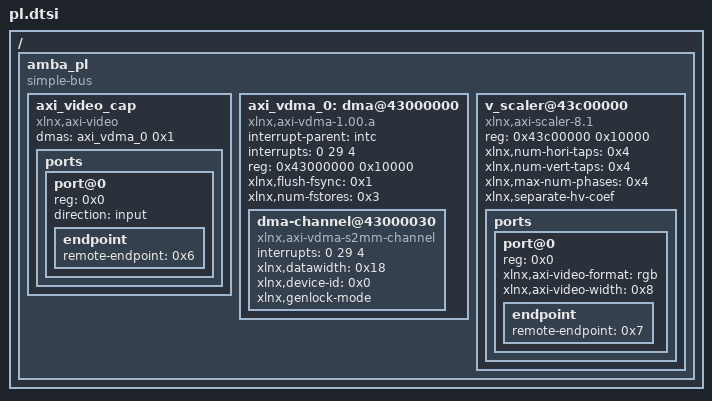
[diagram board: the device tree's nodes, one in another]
/*
 * CAUTION: This file is automatically generated by Xilinx.
 * Version:  
 * Today is: Sat Mar 12 11:05:37 2016
*/


/ {
	amba_pl: amba_pl {
		#address-cells = <1>;
		#size-cells = <1>;
		compatible = "simple-bus";
		ranges ;
		
		axi_video_cap {
			compatible = "xlnx,axi-video";
			dmas = <&axi_vdma_0 0x1>;
			dma-names = "port0";

			ports {
				#address-cells = <0x1>;
				#size-cells = <0x0>;

				port@0 {
					reg = <0x0>;
					direction = "input";

					endpoint {
						remote-endpoint = <0x6>;
						linux,phandle = <0x7>;
						phandle = <0x7>;
					};
				};
			};
		};
		
		axi_vdma_0: dma@43000000 {
			#dma-cells = <1>;
			compatible = "xlnx,axi-vdma-1.00.a";
			interrupt-parent = <&intc>;
			interrupts = <0 29 4>;
			reg = <0x43000000 0x10000>;
			xlnx,flush-fsync = <0x1>;
			xlnx,num-fstores = <0x3>;
			dma-channel@43000030 {
				compatible = "xlnx,axi-vdma-s2mm-channel";
				interrupts = <0 29 4>;
				xlnx,datawidth = <0x18>;
				xlnx,device-id = <0x0>;
				xlnx,genlock-mode ;
			};
		};
		
		v_scaler@43c00000 {
			compatible = "xlnx,axi-scaler-8.1";
			reg = <0x43c00000 0x10000>;
			xlnx,num-hori-taps = <0x4>;
			xlnx,num-vert-taps = <0x4>;
			xlnx,max-num-phases = <0x4>;
			xlnx,separate-hv-coef;

			ports {
				#address-cells = <0x1>;
				#size-cells = <0x0>;

				port@0 {
					reg = <0x0>;
					xlnx,axi-video-format = "rgb";
					xlnx,axi-video-width = <0x8>;
					endpoint {
						remote-endpoint = <0x7>;
						linux,phandle = <0x6>;
						phandle = <0x6>;
					};
				};
			};
		};
	};
};
